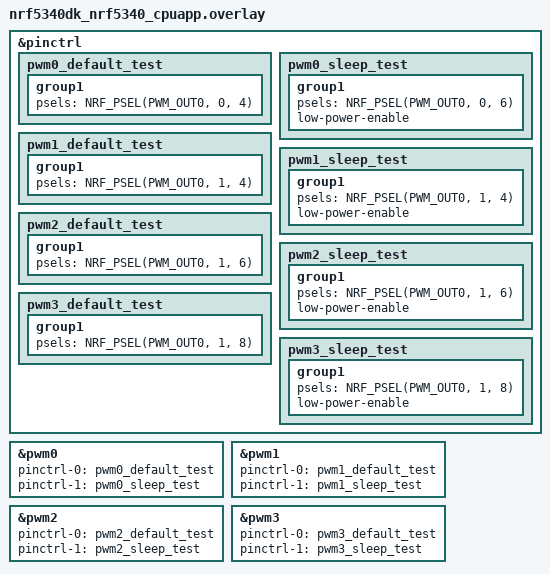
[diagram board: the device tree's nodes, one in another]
/*
 * Copyright (c) 2026 Nordic Semiconductor ASA
 *
 * SPDX-License-Identifier: LicenseRef-Nordic-5-Clause
 */

&pinctrl {
	pwm0_default_test: pwm0_default_test {
		group1 {
			psels = <NRF_PSEL(PWM_OUT0, 0, 4)>;
		};
	};

	pwm0_sleep_test: pwm0_sleep_test {
		group1 {
			psels = <NRF_PSEL(PWM_OUT0, 0, 6)>;
			low-power-enable;
		};
	};

	pwm1_default_test: pwm1_default_test {
		group1 {
			psels = <NRF_PSEL(PWM_OUT0, 1, 4)>;
		};
	};

	pwm1_sleep_test: pwm1_sleep_test {
		group1 {
			psels = <NRF_PSEL(PWM_OUT0, 1, 4)>;
			low-power-enable;
		};
	};

	pwm2_default_test: pwm2_default_test {
		group1 {
			psels = <NRF_PSEL(PWM_OUT0, 1, 6)>;
		};
	};

	pwm2_sleep_test: pwm2_sleep_test {
		group1 {
			psels = <NRF_PSEL(PWM_OUT0, 1, 6)>;
			low-power-enable;
		};
	};

	pwm3_default_test: pwm3_default_test {
		group1 {
			psels = <NRF_PSEL(PWM_OUT0, 1, 8)>;
		};
	};

	pwm3_sleep_test: pwm3_sleep_test {
		group1 {
			psels = <NRF_PSEL(PWM_OUT0, 1, 8)>;
			low-power-enable;
		};
	};
};

&pwm0 {
	status = "okay";
	pinctrl-0 = <&pwm0_default_test>;
	pinctrl-1 = <&pwm0_sleep_test>;
	pinctrl-names = "default", "sleep";
};

&pwm1 {
	status = "okay";
	pinctrl-0 = <&pwm1_default_test>;
	pinctrl-1 = <&pwm1_sleep_test>;
	pinctrl-names = "default", "sleep";
};

&pwm2 {
	status = "okay";
	pinctrl-0 = <&pwm2_default_test>;
	pinctrl-1 = <&pwm2_sleep_test>;
	pinctrl-names = "default", "sleep";
};

&pwm3 {
	status = "okay";
	pinctrl-0 = <&pwm3_default_test>;
	pinctrl-1 = <&pwm3_sleep_test>;
	pinctrl-names = "default", "sleep";
};
